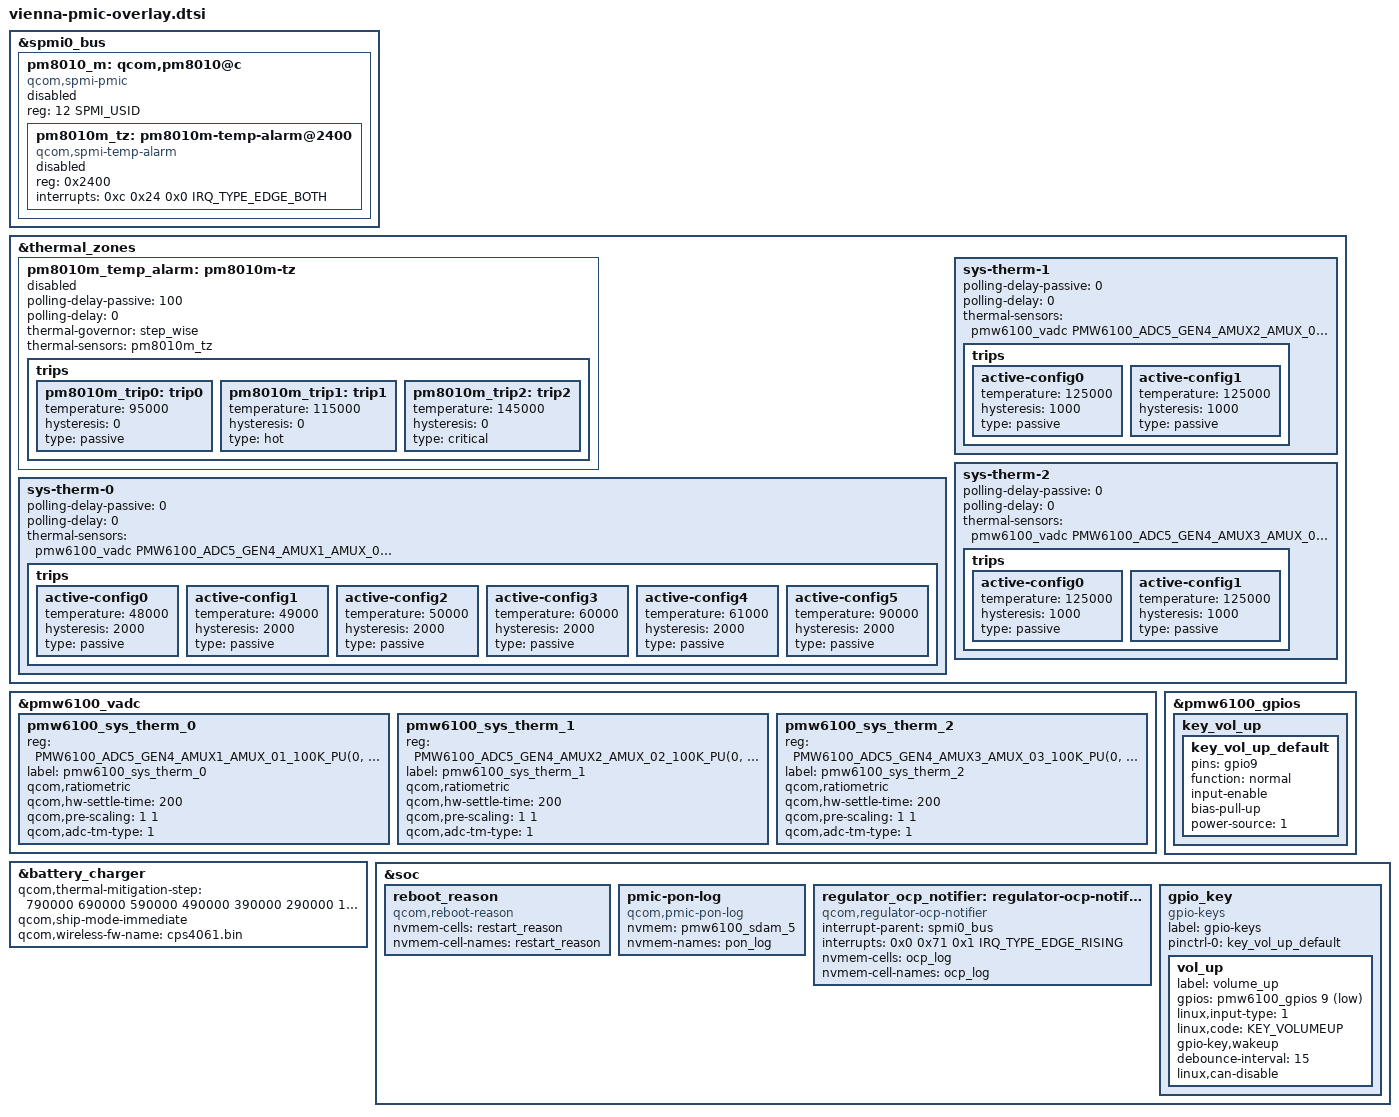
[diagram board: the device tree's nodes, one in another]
// SPDX-License-Identifier: BSD-3-Clause
 /*
  * Copyright (c) Qualcomm Technologies, Inc. and/or its subsidiaries.
  */
#include <dt-bindings/gpio/gpio.h>
#include "pmw6100.dtsi"

&spmi0_bus {
	pm8010_m: qcom,pm8010@c {
		compatible = "qcom,spmi-pmic";
		reg = <12 SPMI_USID>;
		#address-cells = <1>;
		#size-cells = <0>;
		status = "disabled";

		pm8010m_tz: pm8010m-temp-alarm@2400 {
			compatible = "qcom,spmi-temp-alarm";
			reg = <0x2400>;
			interrupts = <0xc 0x24 0x0 IRQ_TYPE_EDGE_BOTH>;
			#thermal-sensor-cells = <0>;
			status = "disabled";
		};
	};
};

&thermal_zones {
	pm8010m_temp_alarm: pm8010m-tz {
		polling-delay-passive = <100>;
		polling-delay = <0>;
		thermal-governor = "step_wise";
		thermal-sensors = <&pm8010m_tz>;
		status = "disabled";

		trips {
			pm8010m_trip0: trip0 {
				temperature = <95000>;
				hysteresis = <0>;
				type = "passive";
			};

			pm8010m_trip1: trip1 {
				temperature = <115000>;
				hysteresis = <0>;
				type = "hot";
			};

			pm8010m_trip2: trip2 {
				temperature = <145000>;
				hysteresis = <0>;
				type = "critical";
			};
		};
	};
};

&pmw6100_vadc {
	pmw6100_sys_therm_0 {
		reg = <PMW6100_ADC5_GEN4_AMUX1_AMUX_01_100K_PU(0, PMW6100_SID)>;
		label = "pmw6100_sys_therm_0";
		qcom,ratiometric;
		qcom,hw-settle-time = <200>;
		qcom,pre-scaling = <1 1>;
		qcom,adc-tm-type = <1>;
	};

	pmw6100_sys_therm_1 {
		reg = <PMW6100_ADC5_GEN4_AMUX2_AMUX_02_100K_PU(0, PMW6100_SID)>;
		label = "pmw6100_sys_therm_1";
		qcom,ratiometric;
		qcom,hw-settle-time = <200>;
		qcom,pre-scaling = <1 1>;
		qcom,adc-tm-type = <1>;
	};

	pmw6100_sys_therm_2 {
		reg = <PMW6100_ADC5_GEN4_AMUX3_AMUX_03_100K_PU(0, PMW6100_SID)>;
		label = "pmw6100_sys_therm_2";
		qcom,ratiometric;
		qcom,hw-settle-time = <200>;
		qcom,pre-scaling = <1 1>;
		qcom,adc-tm-type = <1>;
	};

};

&thermal_zones {
	sys-therm-0 {
		polling-delay-passive = <0>;
		polling-delay = <0>;
		thermal-sensors = <&pmw6100_vadc
				   PMW6100_ADC5_GEN4_AMUX1_AMUX_01_100K_PU(0, PMW6100_SID)>;

		trips {
			active-config0 {
				temperature = <48000>;
				hysteresis = <2000>;
				type = "passive";
			};

			active-config1 {
				temperature = <49000>;
				hysteresis = <2000>;
				type = "passive";
			};

			active-config2 {
				temperature = <50000>;
				hysteresis = <2000>;
				type = "passive";
			};

			active-config3 {
				temperature = <60000>;
				hysteresis = <2000>;
				type = "passive";
			};

			active-config4 {
				temperature = <61000>;
				hysteresis = <2000>;
				type = "passive";
			};

			active-config5 {
				temperature = <90000>;
				hysteresis = <2000>;
				type = "passive";
			};
		};
	};

	sys-therm-1 {
		polling-delay-passive = <0>;
		polling-delay = <0>;
		thermal-sensors = <&pmw6100_vadc
				   PMW6100_ADC5_GEN4_AMUX2_AMUX_02_100K_PU(0, PMW6100_SID)>;

		trips {
			active-config0 {
				temperature = <125000>;
				hysteresis = <1000>;
				type = "passive";
			};

			active-config1 {
				temperature = <125000>;
				hysteresis = <1000>;
				type = "passive";
			};
		};
	};

	sys-therm-2 {
		polling-delay-passive = <0>;
		polling-delay = <0>;
		thermal-sensors = <&pmw6100_vadc
				   PMW6100_ADC5_GEN4_AMUX3_AMUX_03_100K_PU(0, PMW6100_SID)>;

		trips {
			active-config0 {
				temperature = <125000>;
				hysteresis = <1000>;
				type = "passive";
			};

			active-config1 {
				temperature = <125000>;
				hysteresis = <1000>;
				type = "passive";
			};
		};
	};
};

&pmw6100_gpios {
	key_vol_up {
		key_vol_up_default: key_vol_up_default {
			pins = "gpio9";
			function = "normal";
			input-enable;
			bias-pull-up;
			power-source = <1>;
		};
	};
};

&battery_charger {
	qcom,thermal-mitigation-step = <790000 690000 590000 490000 390000 290000 190000>;
	#cooling-cells = <2>;
	qcom,ship-mode-immediate;
	qcom,wireless-fw-name = "cps4061.bin";
};

&soc {
	reboot_reason {
		compatible = "qcom,reboot-reason";
		nvmem-cells = <&restart_reason>;
		nvmem-cell-names = "restart_reason";
	};

	pmic-pon-log {
		compatible = "qcom,pmic-pon-log";
		nvmem = <&pmw6100_sdam_5>;
		nvmem-names = "pon_log";
	};

	regulator_ocp_notifier: regulator-ocp-notifer {
		compatible = "qcom,regulator-ocp-notifier";
		interrupt-parent = <&spmi0_bus>;
		interrupts = <0x0 0x71 0x1 IRQ_TYPE_EDGE_RISING>;
		nvmem-cells = <&ocp_log>;
		nvmem-cell-names = "ocp_log";
	};

	gpio_key {
		compatible = "gpio-keys";
		label = "gpio-keys";
		pinctrl-names = "default";
		pinctrl-0 = <&key_vol_up_default>;
		vol_up {
			label = "volume_up";
			gpios = <&pmw6100_gpios 9 GPIO_ACTIVE_LOW>;
			linux,input-type = <1>;
			linux,code = <KEY_VOLUMEUP>;
			gpio-key,wakeup;
			debounce-interval = <15>;
			linux,can-disable;
		};
	};
};
